# WKUP_CTRL_MMR0_CFG0 register map
Vendor: Texas Instruments
Peripheral module from a debugger description file (folder am65x).
Registers are 32-bit, access per field, reset 0x0 unless marked. A register's access mark holds for its fields unless they carry their own. Offsets are as the file gives them; lines under a group give offsets from that group; [hi:lo] are bit positions; {n}, {i} and the like mark numbered series; 'fields as' and 'values as' point back to an identical list; <NAME> marks a mode.

## WKUP_CTRL_MMR0_CFG0
0x00 CTRLMMR_WKUP_PID ro reset 0x61800212 — Peripheral release details.
  [31:0] REV — TI internal data.
0x08 CTRLMMR_WKUP_MMR_CFG1 ro reset 0x800000DF — Indicates the MMR configuration.
  [7:0] PARTITIONS — Indicates present partitions
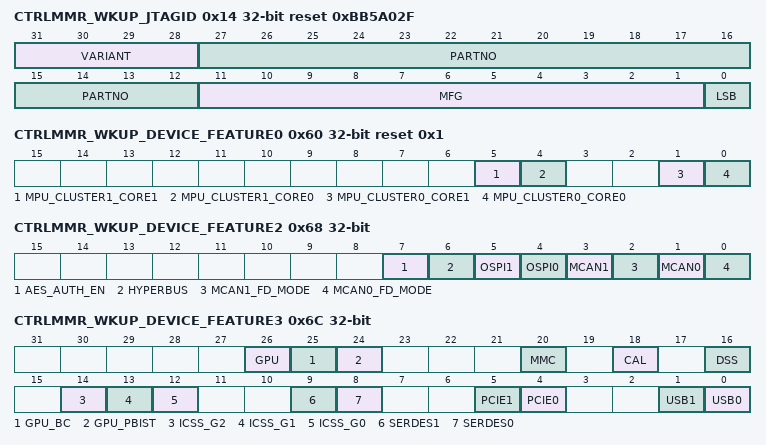
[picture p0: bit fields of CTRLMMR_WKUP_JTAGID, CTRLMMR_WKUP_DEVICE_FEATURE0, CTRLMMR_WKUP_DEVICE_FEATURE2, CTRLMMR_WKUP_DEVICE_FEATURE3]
0x14 CTRLMMR_WKUP_JTAGID ro reset 0xBB5A02F (reset mask 0xFFFFFFF) — The CTRLMMR_WKUP_JTAGID register must be readable by the configuration bus so that this can be accessed via the JTAG and CPU. In Boundary Scan mode, this ID should also be readable with only TCLK present. This means without a valid CPU clock running and also implies that Fusefarm scan is not necessary. The Variant field should be set in the top metal mask so that this may be changed if a future PG is necessary. All other fields may be hard coded.
  [31:28] VARIANT — Indicates device variant
  [27:12] PARTNO — Part number for boundary scan
  [11:1] MFG — Indicates Texas Instruments as manufacturer
  [0] LSB — Always 1
0x18 CTRLMMR_WKUP_JTAG_DEVICE_ID ro reset not defined — This register is used for device identification.
  [31:0] DEVICE_ID — Device information
0x30 CTRLMMR_WKUP_DEVSTAT (reset mask 0xFFFFFC00) — Indicates MCU bootstrap selection. The default value of this register is determined by the MCU bootstrap pins when the por_boot_cfg_srst_n input is de-asserted.
  [9:0] BOOTMODE rw — Indicates MCU boot mode For more information, see
0x34 CTRLMMR_WKUP_BOOTCFG ro (reset mask 0xFFFFFC00) — Indicates MCU bootstrap selection latched at power-on reset by PORz. The default value of this register is determined by the MCU bootstrap pins when the por_boot_cfg_srst_n input is de-asserted and will remain until the MCU bootstrap pins are re-latched on a subsequent por_boot_cfg_srst_n rising edge.
  [9:0] BOOTMODE — Indicates MCU boot mode as latched at power-on reset
0x60 CTRLMMR_WKUP_DEVICE_FEATURE0 ro reset 0x1 (reset mask 0xFFFFFFCD) — Indicates enabled MPU processing elements on the device.
  [5] MPU_CLUSTER1_CORE1 — MPU Cluster1 Core 1 is enabled when set
  [4] MPU_CLUSTER1_CORE0 — MPU Cluster1 Core 0 is enabled when set
  [1] MPU_CLUSTER0_CORE1 — MPU Cluster0 Core 1 is enabled when set
  [0] MPU_CLUSTER0_CORE0 — MPU Cluster0 Core 0 is enabled when set
0x68 CTRLMMR_WKUP_DEVICE_FEATURE2 ro (reset mask 0xFFFFFF00) — Indicates enabled MCU domain interface elements on the device.
  [7] AES_AUTH_EN — AES authentication is enabled in MCU_FlashSS and DMSC when set
  [6] HYPERBUS — MCU_FSS0_HPB0 is enabled when set
  [5] OSPI1 — MCU_OSPI1 is enabled when set
  [4] OSPI0 — MCU_OSPI0 is enabled when set
  [3] MCAN1 — MCU_MCAN1 is enabled when set
  [2] MCAN1_FD_MODE — FD mode is supported on MCU_MCAN1 when set
  [1] MCAN0 — MCU_MCAN0 is enabled when set
  [0] MCAN0_FD_MODE — FD mode is supported on MCU_MCAN0 when set
0x6C CTRLMMR_WKUP_DEVICE_FEATURE3 ro (reset mask 0xF8EA8CCC) — Indicates enabled MAIN domain interface elements on the device.
  [26] GPU — GPU is enabled when set
  [25] GPU_BC — GPU DXT block compression enabled when set
  [24] GPU_PBIST — GPU self-test is enabled when set
  [20] MMC — MMCSD is enabled when set
  [18] CAL — CAL is enabled when set
  [16] DSS — DSS is enabled when set
  [14] ICSS_G2 — ICSS_G2 is enabled when set
  [13] ICSS_G1 — ICSS_G1 is enabled when set
  [12] ICSS_G0 — ICSS_G0 is enabled when set
  [9] SERDES1 — Serdes1 is enabled when set
  [8] SERDES0 — Serdes0 is enabled when set
  [5] PCIE1 — PCIe1 is enabled when set
  [4] PCIE0 — PCIe0 is enabled when set
  [1] USB1 — USB1 is enabled when set
  [0] USB0 — USB0 is enabled when set
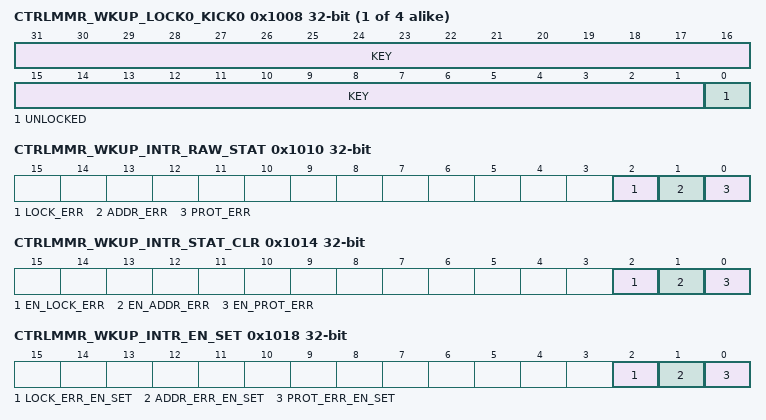
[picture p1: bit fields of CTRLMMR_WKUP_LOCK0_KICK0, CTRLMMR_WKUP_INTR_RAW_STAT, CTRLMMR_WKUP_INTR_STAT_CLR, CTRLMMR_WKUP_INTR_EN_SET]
{0x1008+0x4000*i} CTRLMMR_WKUP_LOCK{i}_KICK0 (i=0..3) — Lower 32-bits of Partition{i} write lock key. This register must be written with the designated key value followed by a write to CTRLMMR_WKUP_LOCK{i}_KICK1 with its key value before write-protected Partition {i} registers can be written.
  [31:1] KEY rw — Write the kick0 unlock value followed by the kick1 unlock value to unlock the write-protected Partition{i} registers
  [0] UNLOCKED ro — Unlock status.
{0x100C+0x4000*i} CTRLMMR_WKUP_LOCK{i}_KICK1 rw (i=0..3) — Upper 32-bits of Partition {i} write lock key. This register must be written with the designated key value after a write to CTRLMMR_WKUP_LOCK{i}_KICK0 with its key value before write-protected Partition {i} registers can be written.
  [31:0] KEY — Write the kick1 unlock value after the kick0 unlock value to unlock the write-protected Partition{i} registers
0x1010 CTRLMMR_WKUP_INTR_RAW_STAT access not given — Shows the interrupt status (before enabling) and allows setting of the interrupt status (for test).
  [2] LOCK_ERR — Lock violation occurred (attempt to write a write-locked register with partition locked) (access W1TS)
  [1] ADDR_ERR — Address violation occurred (attempt to read or write an invalid register address) (access W1TS)
  [0] PROT_ERR — Protection violation occurred (attempt to read or write a register with insufficient security or privilege access rights) (access W1TS)
0x1014 CTRLMMR_WKUP_INTR_STAT_CLR access not given — Shows the enabled interrupt status and allows the interrupt to be cleared.
  [2] EN_LOCK_ERR — Enabled lock interrupt event status (access W1TC)
  [1] EN_ADDR_ERR — Enabled address interrupt event status (access W1TC)
  [0] EN_PROT_ERR — Enabled protection interrupt event status (access W1TC)
0x1018 CTRLMMR_WKUP_INTR_EN_SET access not given — Allows interrupt enables to be set.
  [2] LOCK_ERR_EN_SET — Lock interrupt enable (access W1TS)
  [1] ADDR_ERR_EN_SET — Address interrupt enable (access W1TS)
  [0] PROT_ERR_EN_SET — Protection interrupt enable (access W1TS)
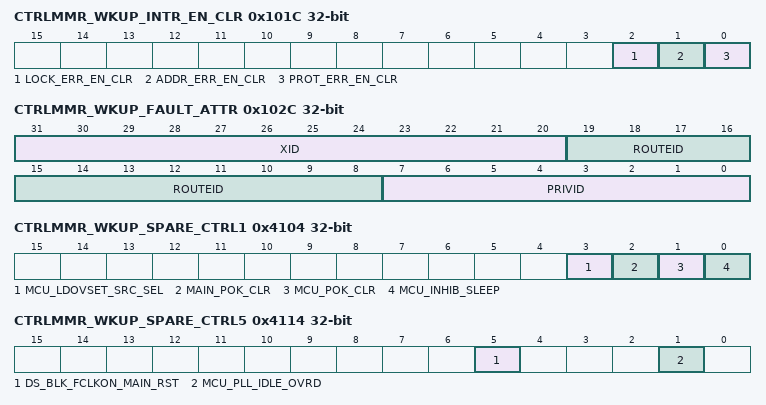
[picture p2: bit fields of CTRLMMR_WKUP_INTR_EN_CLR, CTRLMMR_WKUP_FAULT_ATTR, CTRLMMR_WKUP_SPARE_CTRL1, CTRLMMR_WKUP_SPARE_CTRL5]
0x101C CTRLMMR_WKUP_INTR_EN_CLR access not given — Allows interrupt enables to be cleared.
  [2] LOCK_ERR_EN_CLR — Lock interrupt disable (access W1TC)
  [1] ADDR_ERR_EN_CLR — Address interrupt disable (access W1TC)
  [0] PROT_ERR_EN_CLR — Protection interrupt disable (access W1TC)
0x1024 CTRLMMR_WKUP_FAULT_ADDR ro — Indicates the address of the first transfer that caused a fault to occur.
  [31:0] ADDRESS — Address of the faulted access
0x1028 CTRLMMR_WKUP_FAULT_TYPE ro — Indicates the access type of the first transfer that caused a fault to occur.
  [5:0] TYPE — Type of access which faulted 0h - No fault 1h - User execute access 2h - User write access 4h - User read access 8h - Supervisor execute access 10h - Supervisor write access 20h - Supervisor read access
0x102C CTRLMMR_WKUP_FAULT_ATTR ro — Indicates the attributes of the first transfer that caused a fault to occur.
  [31:20] XID — Transaction ID
  [19:8] ROUTEID
  [7:0] PRIVID — Privilege ID
0x1030 CTRLMMR_WKUP_FAULT_CLR access not given — Allows software to clear the current fault Clearing the current fault allows the CTRLMMR_WKUP_FAULT_ADDR, CTRLMMR_WKUP_FAULT_TYPE, and CTRLMMR_WKUP_FAULT_ATTR registers to latch the attributes of the next fault that occurs. This does not affect the fault interrupt event itself. The interrupt must be cleared using the appropriate INTR_STATUS_CLR register bits.
  [0] CLEAR — Fault clear (access W1TC)
0x4004 CTRLMMR_WKUP_MAIN_PWR_CTRL reset 0x1 — Controls power options for the MAIN voltage domain.
  [0] PWR_EN rw — When set, drives the PMIC_PWR_EN1 output to turn on the MAIN voltage domain
0x4020 CTRLMMR_WKUP_GPIO_CTRL — Controls operation of the WKUP_GPIO module.
  [0] WAKEN rw — Enables WKUP_GPIO wakeup event operation by controling the WKUP_GPIO LPSC clockstop_ack behavior. 0h - No WKUP_GPIO wakeup support. WKUP_GPIO vbus clock is gated on clkstop_ack from WKUP_GPIO to LPSC 1h - WKUP_GPIO wakeup enabled. WKUP_GPIO vbus clock is NOT gated on LPSC clockstop_req. WKUP_GPIO LPSC clkstop_ack input is driven by clkstop_req output.
0x4104 CTRLMMR_WKUP_SPARE_CTRL1 rw
  [3] MCU_LDOVSET_SRC_SEL — Determines the source of the MCU SRAM LDO trim bits
  [2] MAIN_POK_CLR — When set, resets pgood sticky bits for all MAIN domain voltage POK detection.
  [1] MCU_POK_CLR — When set, resets pgood sticky bits for WKUP core, PMIC. MCU core, WKUP 3.3V IO, and WKUP 1.8V IO voltage POK detection.
  [0] MCU_INHIB_SLEEP — Prevents LPSC_MCU_COMMON peripherals from being reset on a MCU warm reset (active low).
0x4114 CTRLMMR_WKUP_SPARE_CTRL5 rw
  [5] DS_BLK_FCLKON_MAIN_RST — During MAIN domain reset, clocks sourced from the MCU domain must remain (forced) active until reset is complete (efuse scan completed) to ensure reset propogation to MAIN domain modules using those clocks. This bit is used (should be set) to block those clocks from propogating during deep sleep mode.
  [1] MCU_PLL_IDLE_OVRD — MCU PLL idle override.
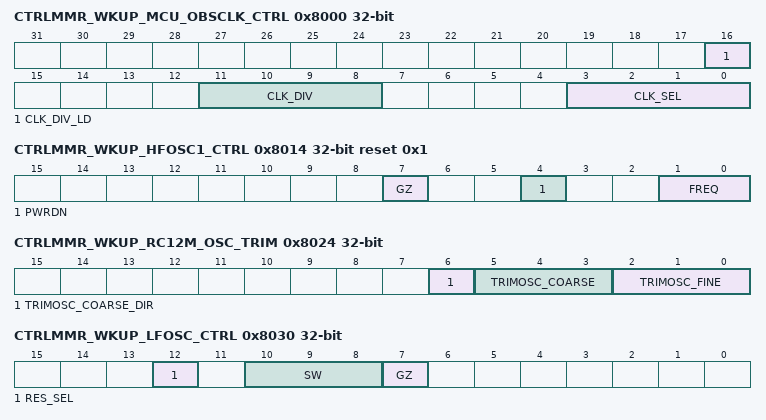
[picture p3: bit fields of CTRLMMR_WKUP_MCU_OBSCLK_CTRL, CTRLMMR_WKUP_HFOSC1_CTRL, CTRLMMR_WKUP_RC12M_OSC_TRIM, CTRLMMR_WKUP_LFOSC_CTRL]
0x8000 CTRLMMR_WKUP_MCU_OBSCLK_CTRL — Controls which internal clock is made observable on the MCU_OBSCLK output pin.
  [16] CLK_DIV_LD rw — Load the output divider value
  [11:8] CLK_DIV rw — MCU_OBSCLK pin output divider
  [3:0] CLK_SEL rw — MCU_OBSCLK pin output selection 0h - CLK_12M_RC 1h - HFOSC0_CLK 2h - MCU_PLL_CLKOUT 3h - MCU_PLLCTL_OBSCLK 4h - MCUHSDIV_CLKOUT1 5h - MCUHSDIV_CLKOUT2 6h - MCUHSDIV_CLKOUT3 7h - MCUHSDIV_CLKOUT4 8h - CPSW_PLL_CLKOUT 9h - CLK_32K_RC Ah - CPSWHSDIV_CLKOUT1 Bh - CPSWHSDIV_CLKOUT2 Ch - CPSWHSDIV_CLKOUT3 Dh - CPSWHSDIV_CLKOUT4 Eh - '0' Fh - LPXOSC_CLKOUT
0x8014 CTRLMMR_WKUP_HFOSC1_CTRL reset 0x1 — Added Note for CTRLMMR_WKUP_HFOSC1_CTRL Register Use This register controls high-frequency oscillator – HFOSC1, located in MAIN domain. Controls the operation of oscillator 1.
  [7] GZ rw — Oscillator disable. When GZ=1 the both bypass and oscillation mode are disabled.
  [4] PWRDN rw — Oscillator powerdown. When set, places the oscillator in Bypass mode. This has no effect if the GZ bit is set.
  [1:0] FREQ rw — Bits 0-1 control the OSC HFENABLE and XHFENABLE inputs, respectively to select the required frequency of oscillation. These bits must be set before oscillator startup and cannot be changed dynamically while the oscillator is running. 0h - &lt;19.2 MHz 1h - 19.2 - 32 MHz 2h - 38 - 52 MHz 3h - 38 - 52 MHz
0x8024 CTRLMMR_WKUP_RC12M_OSC_TRIM (reset mask 0xFFFFFF80) — Provides frequency trimming for the 12.5 MHz RC oscillator module.
  [6] TRIMOSC_COARSE_DIR rw — Coarse adjustment direction. If output is greater than 12.5
  [5:3] TRIMOSC_COARSE rw — Coarse adjustment. Frequency is decreased or increased by 1.25 MHz per value based on the trimosc_coarse_dir value.
  [2:0] TRIMOSC_FINE rw — Fine adjustment. Decreases the frequency by 250 KHz per value.
0x8030 CTRLMMR_WKUP_LFOSC_CTRL — Controls the operation of the low frequency oscillator module.
  [12] RES_SEL rw — Oscillator external feedback resistor select
  [10:8] SW rw — Oscillator gain adjustment
  [7] GZ rw — Oscillator disable. When GZ=1 the both bypass and oscillation mode are disabled.
0x8050 CTRLMMR_WKUP_MCU_PLL_CLKSEL — Controls the clock source for MCU voltage domain PLL[1:0].
  [8] CLKLOSS_SWTCH_EN rw — When set, enables automatic switching of MCU PLL[1:0] clock source to CLK_12M_RC if HFOSC0 clock loss is detected
0x8060 CTRLMMR_WKUP_PER_CLKSEL — Controls the wakeup peripheral functional clock source. Allows the main oscillator to be used as the functional clock source for the WKUP_USART and WKUP_I2C when PLLs are powered down.
  [0] MCUPLL_BYPASS rw — Select the main oscillator clock rather than the PLL generated clock as the functional clock (PLL BYPASS mode).
0x8064 CTRLMMR_WKUP_USART_CLKSEL — Controls the functional clock source for WKUP_USART0.
  [0] CLK_SEL rw — WKUP_USART0 FCLK selection
0x8070 CTRLMMR_WKUP_GPIO_CLKSEL — Controls the functional clock source for WKUP_GPIO.
  [1:0] WAKE_CLK_SEL rw — WKUP_GPIO clock selection. Must be set to MCU_SYSCLK0/4 whenever WKUP_GPIO VBUS interface is enabled. Other clock source may be selected as a wake up clock for DeepSleep modes after WKUP_GPIO is gated off through LPSC. 0h - MCU_SYSCLK0 / 4 1h - MCU_SYSCLK0 / 4 2h - CLK_32K_RC 3h - CLK_12M_RC
0x8080 CTRLMMR_WKUP_MAIN_PLL0_CLKSEL — Controls the clock source for MAIN voltage domain PLL0.
  [0] CLK_SEL rw — Selects the clock source for PLL0
0x8084 CTRLMMR_WKUP_MAIN_PLL1_CLKSEL — Controls the clock source for MAIN voltage domain PLL1.
  [0] CLK_SEL rw — Selects the clock source for PLL1
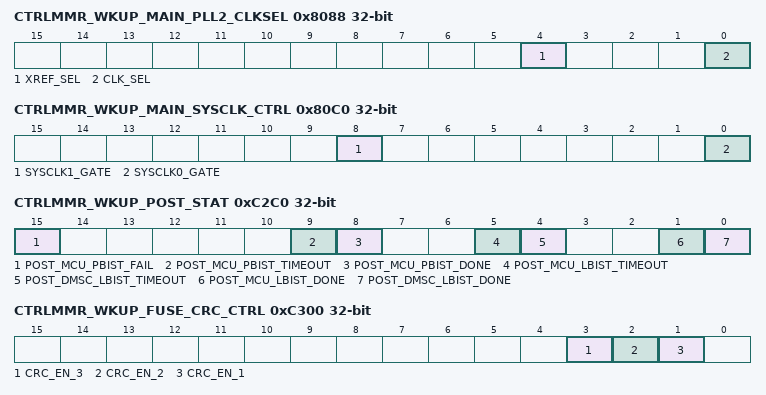
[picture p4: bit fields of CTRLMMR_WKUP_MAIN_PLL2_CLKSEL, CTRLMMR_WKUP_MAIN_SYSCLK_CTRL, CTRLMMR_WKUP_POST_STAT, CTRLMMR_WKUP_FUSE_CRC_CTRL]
0x8088 CTRLMMR_WKUP_MAIN_PLL2_CLKSEL — Controls the clock source for MAIN voltage domain PLL2.
  [4] XREF_SEL rw — Selects the alternate clock source for PLL2
  [0] CLK_SEL rw — Selects the clock source for PLL2
0x808C CTRLMMR_WKUP_MAIN_PLL3_CLKSEL — Controls the clock source for MAIN voltage domain PLL3.
  [0] CLK_SEL rw — Selects the clock source for PLL3
0x8090 CTRLMMR_WKUP_MAIN_PLL4_CLKSEL — Controls the clock source for MAIN voltage domain PLL4.
  [0] CLK_SEL rw — Selects the clock source for PLL4
0x8098 CTRLMMR_WKUP_MAIN_PLL6_CLKSEL — Controls the clock source for MAIN voltage domain PLL6.
  [0] CLK_SEL rw — Selects the clock source for PLL6
0x809C CTRLMMR_WKUP_MAIN_PLL7_CLKSEL — Controls the clock source for MAIN voltage domain PLL7.
  [0] CLK_SEL rw — Selects the clock source for PLL7
0x80C0 CTRLMMR_WKUP_MAIN_SYSCLK_CTRL — Controls clock gating of the MAIN PLL Controller SYSCLK outputs.
  [8] SYSCLK1_GATE rw — When set, gates off SYSCLK1 output of the MAIN PLL Controller
  [0] SYSCLK0_GATE rw — When set, gates off SYSCLK0 (CLK1) output of the MAIN PLL Controller
0xC2C0 CTRLMMR_WKUP_POST_STAT ro (reset mask 0xFFFF7CCC) — Contains the result of power-on self tests.
  [15] POST_MCU_PBIST_FAIL — MCU PBIST failed
  [9] POST_MCU_PBIST_TIMEOUT — MCU PBIST timed out
  [8] POST_MCU_PBIST_DONE — MCU PBIST done
  [5] POST_MCU_LBIST_TIMEOUT — MCU LBIST timed out
  [4] POST_DMSC_LBIST_TIMEOUT — DMSC LBIST timed out
  [1] POST_MCU_LBIST_DONE — MCU LBIST done
  [0] POST_DMSC_LBIST_DONE — DMSC LBIST done
0xC300 CTRLMMR_WKUP_FUSE_CRC_CTRL — Controls WKUP efuse chain CRC calculation.
  [3] CRC_EN_3 rw — Enable eFuse CRC calculation for chain 3
  [2] CRC_EN_2 rw — Enable eFuse CRC calculation for chain 2
  [1] CRC_EN_1 rw — Enable eFuse CRC calculation for chain 1
{0xC300+4i} CTRLMMR_WKUP_CHAIN{i}_CRC_FUSE ro reset not defined (i=1..3) — Indicates the stored CRC for WKUP fuse chain {i}.
  [31:0] CRC — Stored chain CRC
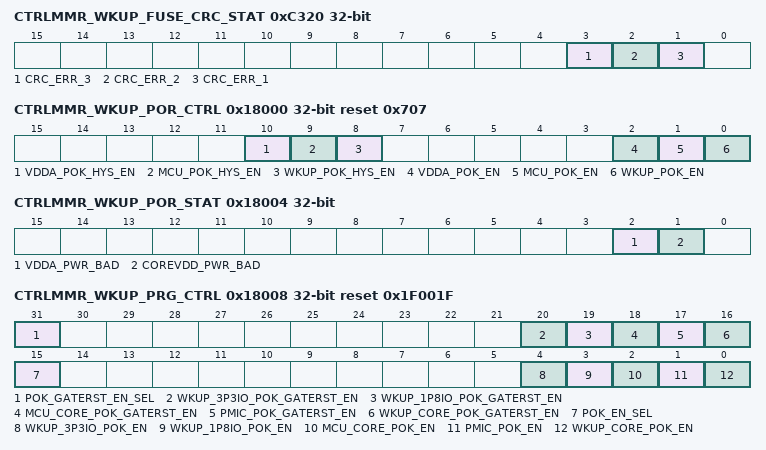
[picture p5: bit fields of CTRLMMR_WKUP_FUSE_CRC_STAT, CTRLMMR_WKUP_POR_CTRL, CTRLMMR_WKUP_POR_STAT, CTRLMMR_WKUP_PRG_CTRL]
0xC320 CTRLMMR_WKUP_FUSE_CRC_STAT ro (reset mask 0xFFFFFFF1) — Indicates status of fuse chain CRC.
  [3] CRC_ERR_3 — Indicates eFuse CRC error on chain 3
  [2] CRC_ERR_2 — Indicates eFuse CRC error on chain 2
  [1] CRC_ERR_1 — Indicates eFuse CRC error on chain 1
{0xC320+4i} CTRLMMR_WKUP_CHAIN{i}_CRC_CALC ro reset not defined (i=1..3) — Indicates the calculated CRC for WKUP fuse chain {i}.
  [31:0] CRC — Calculated chain CRC
0x18000 CTRLMMR_WKUP_POR_CTRL reset 0x707 — Configures Power-on reset behavior.
  [10] VDDA_POK_HYS_EN rw — Enable WKUP analog voltage coarse POK hysteresis
  [9] MCU_POK_HYS_EN rw — Enable MCU core voltage coarse POK hysteresis
  [8] WKUP_POK_HYS_EN rw — Enable WKUP core voltage coarse POK hysteresis
  [2] VDDA_POK_EN rw — Enable coarse Power-OK detection on WKUP 1.8V analog voltage using the VDDA_MON pin
  [1] MCU_POK_EN rw — Enable coarse Power-OK detection on MCU core voltage using the VDD_MCU_MON pin
  [0] WKUP_POK_EN rw — Enable coarse Power-OK detection on WKUP core voltage using the VDD_WKUP_MON pin
0x18004 CTRLMMR_WKUP_POR_STAT ro (reset mask 0xFFFFFFF9) — Shows Power-on reset status.
  [2] VDDA_PWR_BAD — WKUP analog voltage coarse POK.
  [1] COREVDD_PWR_BAD — MCU/WKUP core voltage coarse POK.
0x18008 CTRLMMR_WKUP_PRG_CTRL reset 0x1F001F — Configures the WKUP domain PRG controller.
  [31] POK_GATERST_EN_SEL rw — Select POK reset gating enable source
  [20] WKUP_3P3IO_POK_GATERST_EN rw — Enable 3.3 volt voltage POK detection reset gating
  [19] WKUP_1P8IO_POK_GATERST_EN rw — Enable 1.8 volt voltage POK detection reset gating
  [18] MCU_CORE_POK_GATERST_EN rw — Enable MCU core voltage POK detection reset gating
  [17] PMIC_POK_GATERST_EN rw — Enable PMIC voltage POK detection reset gating
  [16] WKUP_CORE_POK_GATERST_EN rw — Enable WKUP core voltage POK detection reset gating
  [15] POK_EN_SEL rw — Select POK enable source
  [4] WKUP_3P3IO_POK_EN rw — Enable WKUP 3.3V IO voltage POK detection
  [3] WKUP_1P8IO_POK_EN rw — Enable WKUP 1.8V IO voltage POK detection
  [2] MCU_CORE_POK_EN rw — Enable MCU core voltage POK detection
  [1] PMIC_POK_EN rw — Enable PMIC voltage POK detection
  [0] WKUP_CORE_POK_EN rw — Enable WKUP core voltage POK detection
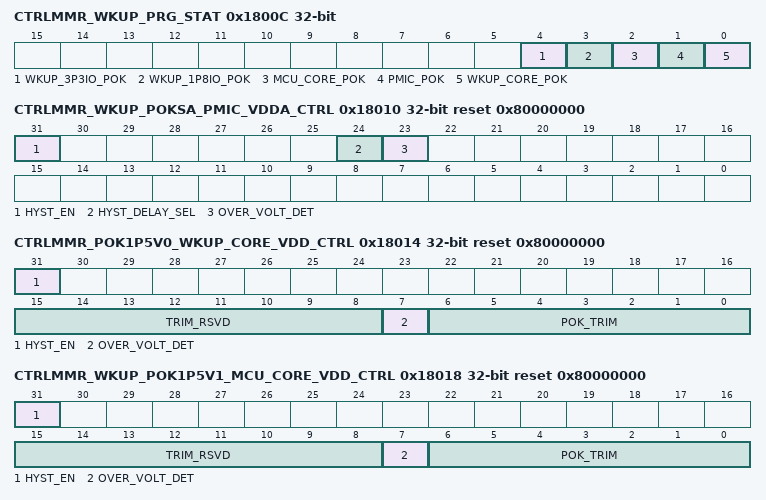
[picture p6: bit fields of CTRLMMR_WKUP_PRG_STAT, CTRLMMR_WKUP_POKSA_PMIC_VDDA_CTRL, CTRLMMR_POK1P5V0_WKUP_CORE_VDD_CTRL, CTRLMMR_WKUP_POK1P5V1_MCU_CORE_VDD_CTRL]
0x1800C CTRLMMR_WKUP_PRG_STAT ro (reset mask 0xFFFFFFE0) — Provides WKUP domain PRG controller status.
  [4] WKUP_3P3IO_POK — WKUP 3.3V IO voltage POK
  [3] WKUP_1P8IO_POK — WKUP 1.8V IO voltage POK
  [2] MCU_CORE_POK — MCU core voltage POK
  [1] PMIC_POK — PMIC voltage POK
  [0] WKUP_CORE_POK — WKUP core voltage POK
0x18010 CTRLMMR_WKUP_POKSA_PMIC_VDDA_CTRL reset 0x80000000 (reset mask 0xFF7FFFFF) — Controls operation of the PMIC (0.5V) voltage POK module.
  [31] HYST_EN rw — Enable POK hysteresis
  [24] HYST_DELAY_SEL rw — Selects the delay time used for POK hysteresis
  [23] OVER_VOLT_DET rw — Over / under voltage detection mode
0x18014 CTRLMMR_POK1P5V0_WKUP_CORE_VDD_CTRL reset 0x80000000 (reset mask 0xFFFF0000) — Controls operation of the WKUP core (1V) voltage POK module.
  [31] HYST_EN rw — Enable POK hysteresis
  [15:8] TRIM_RSVD rw — Reserved trim bits.
  [7] OVER_VOLT_DET rw — Over / under voltage detection mode
  [6:0] POK_TRIM rw — POK trim bits. These bits are used to trim the comparator threshold voltage. Trim granularity is dependent on hyst_en and pok_trim bit settings.
0x18018 CTRLMMR_WKUP_POK1P5V1_MCU_CORE_VDD_CTRL reset 0x80000000 (reset mask 0xFFFF0000) — Controls operation of the MCU core (1V) voltage POK module.
  fields as CTRLMMR_POK1P5V0_WKUP_CORE_VDD_CTRL
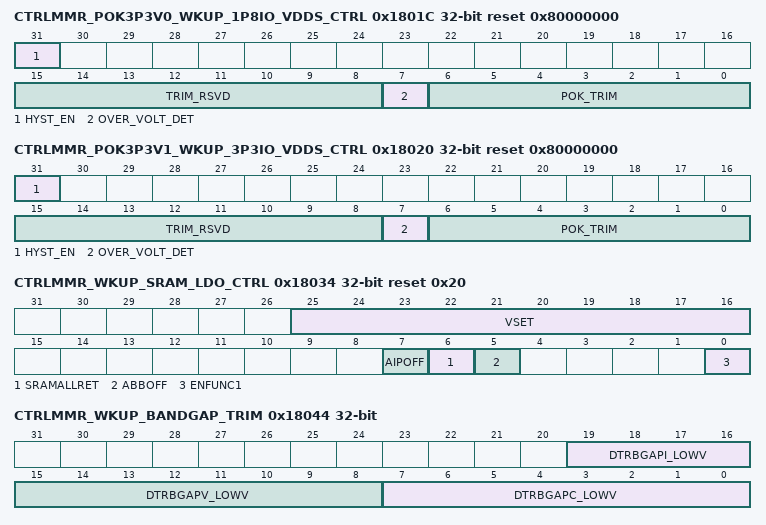
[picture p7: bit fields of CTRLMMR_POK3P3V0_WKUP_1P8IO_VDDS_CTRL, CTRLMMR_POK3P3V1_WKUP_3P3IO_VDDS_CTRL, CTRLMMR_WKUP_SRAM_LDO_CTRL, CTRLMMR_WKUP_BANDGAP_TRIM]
0x1801C CTRLMMR_POK3P3V0_WKUP_1P8IO_VDDS_CTRL reset 0x80000000 (reset mask 0xFFFF0000) — Controls operation of the WKUP 1.8 volt IO voltage POK module.
  fields as CTRLMMR_POK1P5V0_WKUP_CORE_VDD_CTRL
0x18020 CTRLMMR_POK3P3V1_WKUP_3P3IO_VDDS_CTRL reset 0x80000000 (reset mask 0xFFFF0000) — Controls operation of the WKUP 3.3 volt IO POK module.
  fields as CTRLMMR_POK1P5V0_WKUP_CORE_VDD_CTRL
0x18030 CTRLMMR_WKUP_LDO_CTRL (reset mask 0xFFFFFFC0) — Controls operation of the WKUP LDO module.
  [5:0] LDO_PROG rw — LDO output programming bits.
0x18034 CTRLMMR_WKUP_SRAM_LDO_CTRL reset 0x20 (reset mask 0xFC00FFFF) — Controls operation of the WKUP SRAM LDO module.
  [25:16] VSET rw — LDO trim bits
  [7] AIPOFF rw — When set, disables the VSLDO and enables IDDQ test mode
  [6] SRAMALLRET rw — When set, places the VSLDO in retention mode
  [5] ABBOFF rw — When set, shorts the VNWA voltage to VDDAR
  [0] ENFUNC1 rw — Control the LDO loop dynamics. Setting enfunc0 decreases loop gain by 6dB.
0x18044 CTRLMMR_WKUP_BANDGAP_TRIM (reset mask 0xFFF00000) — Trims the WKUP LDO Bandgap Regulator.
  [19:16] DTRBGAPI_LOWV rw — Bandgap output current trim bits
  [15:8] DTRBGAPV_LOWV rw — Bandgap output voltage magnitude trim bits
  [7:0] DTRBGAPC_LOWV rw — Bandgap slope trim bits. Bit7 is used to calculate the offset
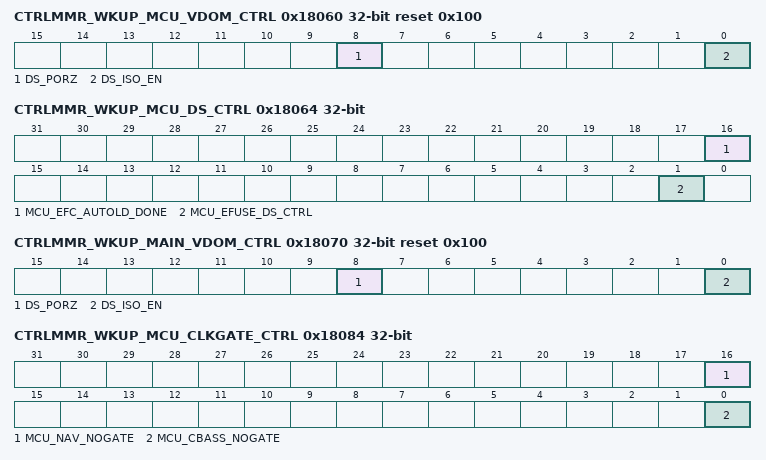
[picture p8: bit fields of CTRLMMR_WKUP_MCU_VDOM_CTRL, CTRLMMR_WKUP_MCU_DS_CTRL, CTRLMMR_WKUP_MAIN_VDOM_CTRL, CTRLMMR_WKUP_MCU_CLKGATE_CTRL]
0x18060 CTRLMMR_WKUP_MCU_VDOM_CTRL reset 0x100 — Provides MCU voltage domain isolation for deeper sleep operation.
  [8] DS_PORZ rw — When low asserts POR_RST_n to the MCU Domain. This bit should be cleared by the DMSC after completing MCU domain isolation to force the MCU domain into reset when implementing DeeperSleep mode. Bit must be set back to 1 by DMSC In order to bring the MCU domain out of reset.
  [0] DS_ISO_EN rw — MCU deep sleep isolation enable. This bit should be set prior to powering off the MCU voltage domain to ensure proper signal isolation.
0x18064 CTRLMMR_WKUP_MCU_DS_CTRL (reset mask 0xFFFEFFFF) — Used to control entry and exit from DeepSleep power mode.
  [16] MCU_EFC_AUTOLD_DONE ro — Indicates efuse autoload scan completion
  [1] MCU_EFUSE_DS_CTRL rw — Gate WKUP efuse scan chains. This bit must be set to 1 before setting MCU_VDOM_CTRL_ds_iso_en to prevent rescan of WKUP efuses upon DeepSLeep mode exit. This bit should be cleared only after mcu_efc_autold_done is set on wakeup from DeepSLeep mode.
0x18070 CTRLMMR_WKUP_MAIN_VDOM_CTRL reset 0x100 — Provides MAIN voltage domain isolation for deep sleep operation.
  [8] DS_PORZ rw — When low, asserts POR_RST_n to the MAIN Domain. This bit should be cleared by the DMSC after completing MAIN domain isolation to force the MAIN domain into reset when implementing DeeperSleep mode. Bit must be set back to 1 by DMSC In order to bring the MAIN domain out of reset.
  [0] DS_ISO_EN rw — MAIN deep sleep isolation enable. This bit should be set prior to powering off the MAIN voltage domain to ensure proper signal isolation.
0x18084 CTRLMMR_WKUP_MCU_CLKGATE_CTRL (reset mask 0xFFFEFFFE) — Controls the power clock gating feature of MCU domain modules and busses. This register is present on SR2.0 only.
  [16] MCU_NAV_NOGATE rw — MCU NavSS interface clock gate disable
  [0] MCU_CBASS_NOGATE rw — MCU domain bus clock gate disable
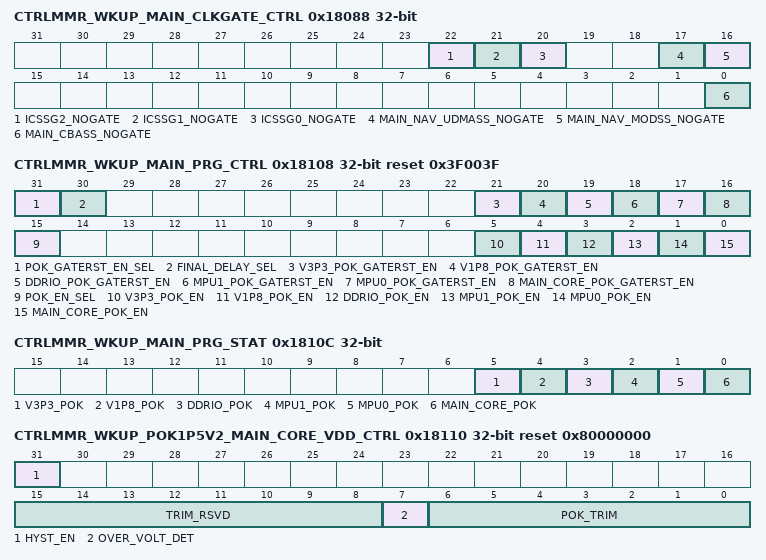
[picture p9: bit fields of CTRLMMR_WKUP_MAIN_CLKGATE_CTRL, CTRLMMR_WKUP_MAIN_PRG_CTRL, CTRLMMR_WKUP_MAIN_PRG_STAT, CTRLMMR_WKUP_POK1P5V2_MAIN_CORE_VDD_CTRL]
0x18088 CTRLMMR_WKUP_MAIN_CLKGATE_CTRL (reset mask 0xFF8CFFFE) — Controls the power clock gating feature of MAIN domain modules and busses. This register is present on SR2.0 only.
  [22] ICSSG2_NOGATE rw — ICSS_G2 interface clock gate disable
  [21] ICSSG1_NOGATE rw — ICSS_G1 interface clock gate disable
  [20] ICSSG0_NOGATE rw — ICSS_G0 interface clock gate disable
  [17] MAIN_NAV_UDMASS_NOGATE rw — Main NavSS UDMASS interface clock gate disable
  [16] MAIN_NAV_MODSS_NOGATE rw — Main NavSS MODSS interface clock gate disable
  [0] MAIN_CBASS_NOGATE rw — Main domain bus clock gate disable
0x180A0 CTRLMMR_WKUP_TEMP_DIODE_TRIM (reset mask 0xFFFFC000) — Trims the silicon junction temperature diode.
  [13:0] TRIM rw — Sets the diode non-ideality factor (n), starting from 100th place decimal and going down
0x18108 CTRLMMR_WKUP_MAIN_PRG_CTRL reset 0x3F003F — Configures the MAIN domain PRG controller.
  [31] POK_GATERST_EN_SEL rw — Select POK reset gating enable source
  [30] FINAL_DELAY_SEL rw — Selects the reset output delay
  [21] V3P3_POK_GATERST_EN rw — Enable 3.3 volt voltage POK detection reset gating
  [20] V1P8_POK_GATERST_EN rw — Enable 1.8 volt voltage POK detection reset gating
  [19] DDRIO_POK_GATERST_EN rw — Enable DDRIO voltage POK detection reset gating
  [18] MPU1_POK_GATERST_EN rw — Enable MPU1 core voltage POK detection reset gating
  [17] MPU0_POK_GATERST_EN rw — Enable MPU0 core voltage POK detection reset gating
  [16] MAIN_CORE_POK_GATERST_EN rw — Enable MAIN core voltage POK detection reset gating
  [15] POK_EN_SEL rw — Select POK enable source
  [5] V3P3_POK_EN rw — Enable 3.3 volt voltage POK detection
  [4] V1P8_POK_EN rw — Enable 1.8 volt voltage POK detection
  [3] DDRIO_POK_EN rw — Enable DDR IO voltage POK detection
  [2] MPU1_POK_EN rw — Enable MPU1 voltage POK detection
  [1] MPU0_POK_EN rw — Enable MPU0 voltage POK detection
  [0] MAIN_CORE_POK_EN rw — Enable MAIN core voltage POK detection
0x1810C CTRLMMR_WKUP_MAIN_PRG_STAT ro (reset mask 0xFFFFFFC0) — Provides MAIN domain PRG controller status.
  [5] V3P3_POK — 3.3 volt voltage POK
  [4] V1P8_POK — 1.8 volt voltage POK
  [3] DDRIO_POK — DDR IO voltage POK
  [2] MPU1_POK — MPU1 voltage POK
  [1] MPU0_POK — MPU0 voltage POK
  [0] MAIN_CORE_POK — MAIN core voltage POK
0x18110 CTRLMMR_WKUP_POK1P5V2_MAIN_CORE_VDD_CTRL reset 0x80000000 (reset mask 0xFFFF0000) — Controls operation of the MAIN (1V) core voltage POK module.
  fields as CTRLMMR_POK1P5V0_WKUP_CORE_VDD_CTRL
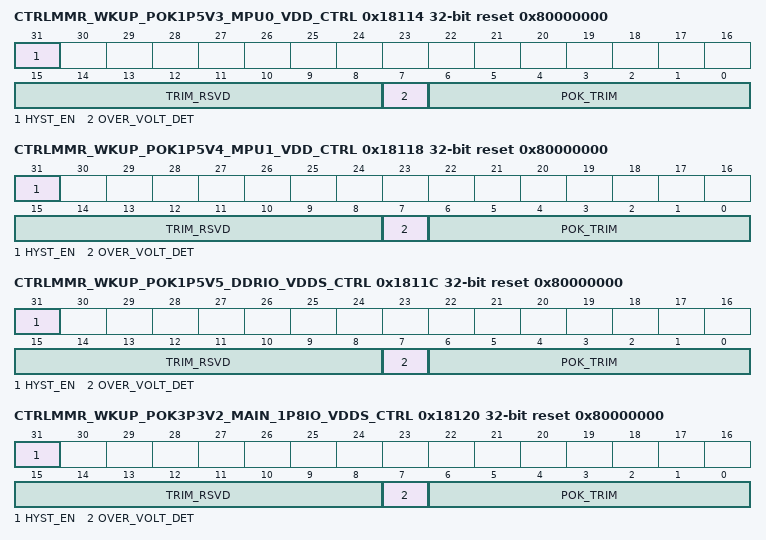
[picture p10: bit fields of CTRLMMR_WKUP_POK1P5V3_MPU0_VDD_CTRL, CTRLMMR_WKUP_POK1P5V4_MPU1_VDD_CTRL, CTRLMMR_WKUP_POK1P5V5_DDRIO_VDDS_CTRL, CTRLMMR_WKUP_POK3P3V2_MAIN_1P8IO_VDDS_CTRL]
0x18114 CTRLMMR_WKUP_POK1P5V3_MPU0_VDD_CTRL reset 0x80000000 (reset mask 0xFFFF0000) — Controls operation of the MPU0 (1V) voltage POK module.
  fields as CTRLMMR_POK1P5V0_WKUP_CORE_VDD_CTRL
0x18118 CTRLMMR_WKUP_POK1P5V4_MPU1_VDD_CTRL reset 0x80000000 (reset mask 0xFFFF0000) — Controls operation of the MPU1 (1V) voltage POK module.
  fields as CTRLMMR_POK1P5V0_WKUP_CORE_VDD_CTRL
0x1811C CTRLMMR_WKUP_POK1P5V5_DDRIO_VDDS_CTRL reset 0x80000000 (reset mask 0xFFFF0000) — Controls operation of the DDR IO voltage POK module.
  fields as CTRLMMR_POK1P5V0_WKUP_CORE_VDD_CTRL
0x18120 CTRLMMR_WKUP_POK3P3V2_MAIN_1P8IO_VDDS_CTRL reset 0x80000000 (reset mask 0xFFFF0000) — Controls operation of the MAIN 1.8 volt IO voltage POK module.
  fields as CTRLMMR_POK1P5V0_WKUP_CORE_VDD_CTRL
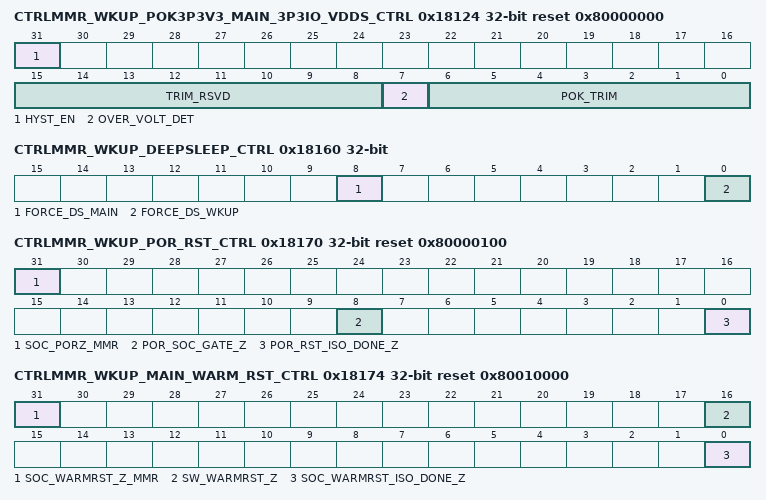
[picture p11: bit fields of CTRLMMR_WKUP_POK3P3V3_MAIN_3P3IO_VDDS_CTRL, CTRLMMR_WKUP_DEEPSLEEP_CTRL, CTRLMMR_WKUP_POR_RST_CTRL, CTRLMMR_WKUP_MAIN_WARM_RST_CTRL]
0x18124 CTRLMMR_WKUP_POK3P3V3_MAIN_3P3IO_VDDS_CTRL reset 0x80000000 (reset mask 0xFFFF0000) — Controls operation of the MAIN 3.3 volt IO voltage POK module.
  fields as CTRLMMR_POK1P5V0_WKUP_CORE_VDD_CTRL
0x18160 CTRLMMR_WKUP_DEEPSLEEP_CTRL — Used to control IO deepsleep operation.
  [8] FORCE_DS_MAIN rw — Force all MAIN IOs into deepsleep mode when set
  [0] FORCE_DS_WKUP rw — Force all WKUP IOs into deepsleep mode when set
0x18170 CTRLMMR_WKUP_POR_RST_CTRL reset 0x80000100 — Controls power-on reset propagation to the MAIN domain. This allows the DMSC to ensure that the MCU domain is properly isolated before the MAIN domain is reset.
  [31] SOC_PORZ_MMR rw — Cleared by DMSC after isolation sequence completion to force SOC_PORz assertion. This bit is set to '1' by CHIP_1_RST_n.
  [8] POR_SOC_GATE_Z rw — Active low signal. Gates propogation of PORz_WKUP to MAIN PRG
  [0] POR_RST_ISO_DONE_Z rw — Reset isolation completion (active low). This bit should be cleared only after reset isolation of the MAIN domain is complete.
0x18174 CTRLMMR_WKUP_MAIN_WARM_RST_CTRL reset 0x80010000 — Controls warm reset propagation to the MAIN domain. This allows the DMSC to ensure that the MCU domain is properly isolated before the MAIN domain is reset.
  [31] SOC_WARMRST_Z_MMR rw — Cleared by DMSC after isolation sequence completion to force SOC_RESETz assertion. This bit is set to '1' on CHIP_1_RST_n.
  [16] SW_WARMRST_Z rw — Cleared by software to issue a warm reset to the Main Domain. (Bit will set on reset of the Main Domain)
  [0] SOC_WARMRST_ISO_DONE_Z rw — Reset isolation completion (active low). This bit should be cleared only after reset isolation of the MAIN domain is complete.
0x18178 CTRLMMR_WKUP_MAIN_RST_STAT ro (reset mask 0xFFFFFFFE) — Shows the reset status of the MAIN domain.
  [0] MAIN_RST_DONE — Indicates MAIN domain reset status.
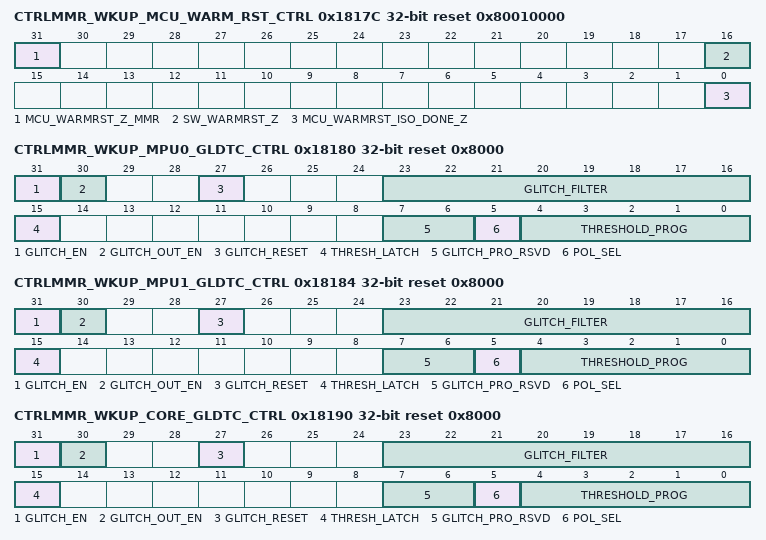
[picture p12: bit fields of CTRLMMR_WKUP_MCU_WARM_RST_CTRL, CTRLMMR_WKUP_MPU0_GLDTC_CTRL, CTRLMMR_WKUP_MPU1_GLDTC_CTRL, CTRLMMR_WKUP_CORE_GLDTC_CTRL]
0x1817C CTRLMMR_WKUP_MCU_WARM_RST_CTRL reset 0x80010000 — Controls warm reset propagation to the MCU domain. This allows the DMSC to ensure that the WKUP domain is properly isolated before the MCU domain is reset.
  [31] MCU_WARMRST_Z_MMR rw — Cleared by DMSC after isolation sequence completion to force MCU_RESETz assertion. This bit is set to '1' on CHIP_1_RST_n
  [16] SW_WARMRST_Z rw — Cleared by software to issue a warm reset to the device (all domains). Bit will set on reset completion.
  [0] MCU_WARMRST_ISO_DONE_Z rw — Reset isolation completion (active low). This bit should be cleared only after reset isolation of the MCU domain is complete.
0x18180 CTRLMMR_WKUP_MPU0_GLDTC_CTRL reset 0x8000 (reset mask 0xFF00FF00) — Controls the MPU cluster0 voltage glitch detector circuit monitoring the VD_MPU0 voltage domain.
  [31] GLITCH_EN rw — Enable glitch detect
  [30] GLITCH_OUT_EN rw — Output enable
  [27] GLITCH_RESET rw — When set, resets the glitch output latch
  [23:16] GLITCH_FILTER rw — Sets the glitch detector filter response. Only bits[3:0] are used. 0h - R = 70.4K, C = 15pF, Filter Corner = 161.42 KHz 11h - R = 66.0K, C = 15pF, Filter Corner = 172.17 KHz 22h - R = 61.6K, C = 15pF, Filter Corner = 184.47 KHz 23h - R = 57.2K, C = 15pF, Filter Corner = 198.66 KHz 44h - R = 52.8K, C = 15pF, Filter Corner = 215.22 KHz 55h - R = 48.4K, C = 15pF, Filter Corner = 234.78 KHz 66h - R = 44.0K, C = 15pF, Filter Corner = 258.26 KHz 77h - R = 39.6K, C = 15pF, Filter Corner = 286.96 KHz 88h - R = 35.2K, C = 15pF, Filter Corner = 322.83 KHz 99h - R = 30.8K, C = 15pF, Filter Corner = 368.94 KHz AAh - R = 26.4K, C = 15pF, Filter Corner = 430.44 KHz BBh - R = 22.0K, C = 15pF, Filter Corner = 516.52 KHz CCh - R = 17.6K, C = 15pF, Filter Corner = 645.66 KHz EDh - R = 13.2K, C = 15pF, Filter Corner = 860.88 KHz EEh - R = 8.8K, C = 15pF, Filter Corner = 1290.00 KHz FFh - R = 4.4K, C = 15pF, Filter Corner = 2500.00 KHz
  [15] THRESH_LATCH rw — Glitch threshold latch. When low, the values in threshold_prog and pol_sel are latched by the Glitch Detector. The user must set thresh_latch back to 1.
  [7:6] GLITCH_PRO_RSVD rw — Reserved for future use
  [5] POL_SEL rw — Selects the polarity of the glitch detection.
  [4:0] THRESHOLD_PROG rw — Programs the glitch threshold as a percentage of the monitored voltage 0h - 0.0% difference from V_Core 1h - 0.2% difference from V_Core 2h - 0.4% difference from V_Core 3h - 0.8% difference from V_Core 4h - 1.2% difference from V_Core 5h - 1.6% difference from V_Core 6h - 2.0% difference from V_Core 7h - 2.8% difference from V_Core 8h - 3.6% difference from V_Core 9h - 4.0% difference from V_Core Ah - 4.4% difference from V_Core Bh - 4.8 % difference from V_Core Ch - 5.2% difference from V_Core Dh - 5.6% difference from V_Core Eh - 6.4% difference from V_Core Fh - 7.2% difference from V_Core 10h - 8.0% difference from V_Core 11h - 8.8% difference from V_Core 12h - 10.4% difference from V_Core 13h - 12.0% difference from V_Core 14h - 14.4% difference from V_Core 15h - 16.8% difference from V_Core 16h - 20.8% difference from V_Core 17h - 30.4% difference from V_Core
0x18184 CTRLMMR_WKUP_MPU1_GLDTC_CTRL reset 0x8000 (reset mask 0xFF00FF00) — Controls the MPU cluster1 voltage glitch detector circuit monitoring the VD_MPU1 voltage domain.
  fields as CTRLMMR_WKUP_MPU0_GLDTC_CTRL
0x18190 CTRLMMR_WKUP_CORE_GLDTC_CTRL reset 0x8000 (reset mask 0xFF00FF00) — Controls the voltage glitch detector circuit monitoring the VD_CORE voltage domain.
  fields as CTRLMMR_WKUP_MPU0_GLDTC_CTRL
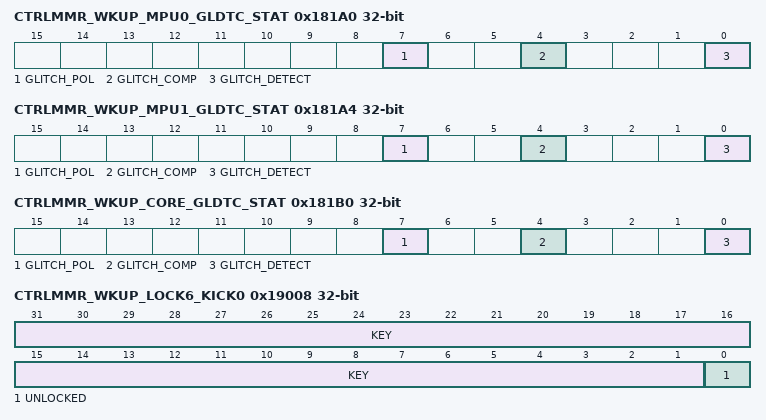
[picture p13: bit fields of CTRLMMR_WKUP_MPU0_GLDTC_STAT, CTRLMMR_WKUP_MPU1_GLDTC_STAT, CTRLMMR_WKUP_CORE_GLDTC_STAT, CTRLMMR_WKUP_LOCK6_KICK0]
0x181A0 CTRLMMR_WKUP_MPU0_GLDTC_STAT ro (reset mask 0xFFFFFF6E) — Shows the status of the MPU cluster0 voltage glitch detector circuit monitoring the VD_MPU0 voltage domain.
  [7] GLITCH_POL — Glitch polarity output
  [4] GLITCH_COMP — (Unlatched) output of the internal glitch comparator
  [0] GLITCH_DETECT — Glitch output latch value
0x181A4 CTRLMMR_WKUP_MPU1_GLDTC_STAT ro (reset mask 0xFFFFFF6E) — Shows the status of the MPU cluster1 voltage glitch detector circuit monitoring the VD_MPU1 voltage domain.
  fields as CTRLMMR_WKUP_MPU0_GLDTC_STAT
0x181B0 CTRLMMR_WKUP_CORE_GLDTC_STAT ro (reset mask 0xFFFFFF6E) — Shows the status of the voltage glitch detector circuit monitoring the VD_CORE voltage domain.
  fields as CTRLMMR_WKUP_MPU0_GLDTC_STAT
0x19008 CTRLMMR_WKUP_LOCK6_KICK0 — Lower 32-bits of Partition6 write lock key. This register must be written with the designated key value followed by a write to CTRLMMR_WKUP_LOCK6_KICK1 with its key value before write-protected Partition 6 registers can be written.
  [31:1] KEY rw — Write the kick0 unlock value followed by the kick1 unlock value to unlock the write-protected Partition6 registers
  [0] UNLOCKED ro — Unlock status.
0x1900C CTRLMMR_WKUP_LOCK6_KICK1 rw — Upper 32-bits of Partition 6 write lock key. This register must be written with the designated key value after a write to CTRLMMR_WKUP_LOCK6_KICK0 with its key value before write-protected Partition 6 registers can be written.
  [31:0] KEY — Write the kick1 unlock value after the kick0 unlock value to unlock the write-protected Partition6 registers
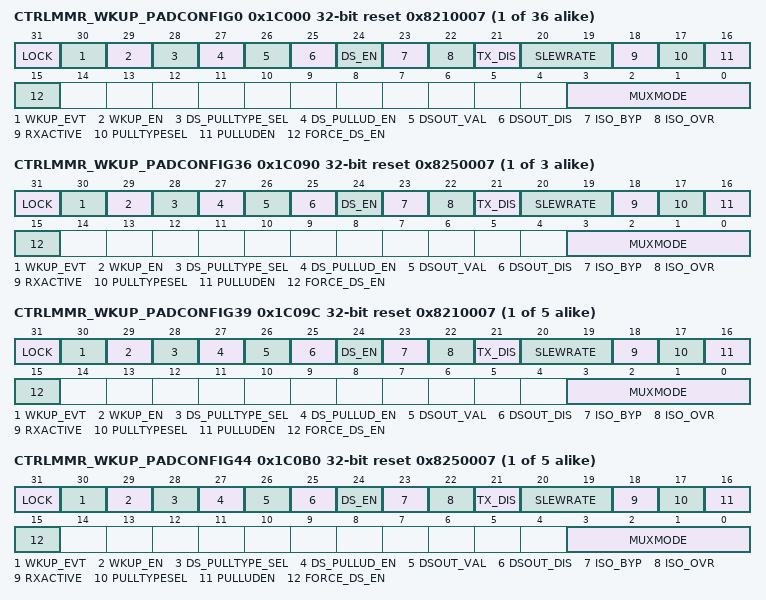
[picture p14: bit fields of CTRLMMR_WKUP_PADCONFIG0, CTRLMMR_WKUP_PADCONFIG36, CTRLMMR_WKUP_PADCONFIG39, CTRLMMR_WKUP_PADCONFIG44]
{0x1C000+4i} CTRLMMR_WKUP_PADCONFIG{i} reset 0x8210007 (i=0..35) — Register to control pin configuration and muxing.
  [31] LOCK rw
  [30] WKUP_EVT ro — Wakeup event status
  [29] WKUP_EN rw — Wakeup enable
  [28] DS_PULLTYPE_SEL rw — Deep Sleep 0 mode pull-up/down selection
  [27] DS_PULLUD_EN rw — Deep Sleep 0 mode pull-up/down enable (active low)
  [26] DSOUT_VAL rw — Deep Sleep 0 mode output value
  [25] DSOUT_DIS rw — Deep Sleep 0 mode output enable
  [24] DS_EN rw — Deep Sleep 0 mode override control
  [23] ISO_BYP rw — Isolation Bypass
  [22] ISO_OVR rw — Isolation Override
  [21] TX_DIS rw — Driver Disable
  [20:19] SLEWRATE rw — Slew rate control selection (CS1, CS0) 0h - 200 MHz 1h - 150 MHz 2h - 100 MHz 3h - 50 MHz
  [18] RXACTIVE rw — Input enable for the Pad
  [17] PULLTYPESEL rw — Pad Pullup / Pulldown type selection
  [16] PULLUDEN rw — Pad Pullup / Pulldown enable. This is an active low signal.
  [15] FORCE_DS_EN rw — Enable pad Deep Sleep controls by overriding DMSC gating
  [3:0] MUXMODE rw — Pad functional signal mux selection 0h - Mux Mode 0 1h - Mux Mode 1 2h - Mux Mode 2 3h - Mux Mode 3 4h - Mux Mode 4 5h - Mux Mode 5 6h - Mux Mode 6 7h - Mux Mode 7 Fh - Mux Mode 15
{0x1C000+4i} CTRLMMR_WKUP_PADCONFIG{i} reset 0x8250007 (i=36..38) — Register to control pin configuration and muxing.
  fields as CTRLMMR_WKUP_PADCONFIG0
{0x1C000+4i} CTRLMMR_WKUP_PADCONFIG{i} reset 0x8210007 (i=39..43) — Register to control pin configuration and muxing.
  fields as CTRLMMR_WKUP_PADCONFIG0
{0x1C000+4i} CTRLMMR_WKUP_PADCONFIG{i} reset 0x8250007 (i=44..48) — Register to control pin configuration and muxing.
  fields as CTRLMMR_WKUP_PADCONFIG0
{0x1C000+4i} CTRLMMR_WKUP_PADCONFIG{i} reset 0x8210007 (i=49..51) — Register to control pin configuration and muxing.
  fields as CTRLMMR_WKUP_PADCONFIG0
0x1C0D0 CTRLMMR_WKUP_PADCONFIG52 reset 0x8250007 — Register to control pin configuration and muxing.
  fields as CTRLMMR_WKUP_PADCONFIG0
0x1C0D4 CTRLMMR_WKUP_PADCONFIG53 reset 0x8250007 — Register to control pin configuration and muxing.
  fields as CTRLMMR_WKUP_PADCONFIG0
0x1C0D8 CTRLMMR_WKUP_PADCONFIG54 reset 0x8210007 — Register to control pin configuration and muxing.
  fields as CTRLMMR_WKUP_PADCONFIG0
0x1C0DC CTRLMMR_WKUP_PADCONFIG55 reset 0x8210007 — Register to control pin configuration and muxing.
  fields as CTRLMMR_WKUP_PADCONFIG0
{0x1C000+4i} CTRLMMR_WKUP_PADCONFIG{i} reset 0x8050000 (i=56..59) — Register to control pin configuration and muxing.
  fields as CTRLMMR_WKUP_PADCONFIG0
0x1C0F0 CTRLMMR_WKUP_PADCONFIG60 reset 0x8010000 — Register to control pin configuration and muxing.
  fields as CTRLMMR_WKUP_PADCONFIG0
0x1C0F4 CTRLMMR_WKUP_PADCONFIG61 reset 0x80C0000 — Register to control pin configuration and muxing.
  fields as CTRLMMR_WKUP_PADCONFIG0
0x1C0F8 CTRLMMR_WKUP_PADCONFIG62 reset 0x82E0000 — Register to control pin configuration and muxing.
  fields as CTRLMMR_WKUP_PADCONFIG0
0x1C0FC CTRLMMR_WKUP_PADCONFIG63 reset 0x8090000 — Register to control pin configuration and muxing.
  fields as CTRLMMR_WKUP_PADCONFIG0
0x1C100 CTRLMMR_WKUP_PADCONFIG64 reset 0x8090000 — Register to control pin configuration and muxing.
  fields as CTRLMMR_WKUP_PADCONFIG0
0x1C104 CTRLMMR_WKUP_PADCONFIG65 reset 0x8260000 — Register to control pin configuration and muxing.
  fields as CTRLMMR_WKUP_PADCONFIG0
0x1C108 CTRLMMR_WKUP_PADCONFIG66 reset 0x8240000 — Register to control pin configuration and muxing.
  fields as CTRLMMR_WKUP_PADCONFIG0
0x1C10C CTRLMMR_WKUP_PADCONFIG67 reset 0x8260000 — Register to control pin configuration and muxing.
  fields as CTRLMMR_WKUP_PADCONFIG0
0x1C110 CTRLMMR_WKUP_PADCONFIG68 reset 0x8260000 — Register to control pin configuration and muxing.
  fields as CTRLMMR_WKUP_PADCONFIG0
0x1C114 CTRLMMR_WKUP_PADCONFIG69 reset 0x8010000 — Register to control pin configuration and muxing.
  fields as CTRLMMR_WKUP_PADCONFIG0
0x1D008 CTRLMMR_WKUP_LOCK7_KICK0 — Lower 32-bits of Partition7 write lock key. This register must be written with the designated key value followed by a write to CTRLMMR_WKUP_LOCK7_KICK1 with its key value before write-protected Partition 7 registers can be written.
  [31:1] KEY rw — Write the kick0 unlock value followed by the kick1 unlock value to unlock the write-protected Partition7 registers
  [0] UNLOCKED ro — Unlock status.
0x1D00C CTRLMMR_WKUP_LOCK7_KICK1 rw — Upper 32-bits of Partition 7 write lock key. This register must be written with the designated key value after a write to CTRLMMR_WKUP_LOCK7_KICK0 with its key value before write-protected Partition 7 registers can be written.
  [31:0] KEY — Write the kick1 unlock value after the kick0 unlock value to unlock the write-protected Partition7 registers
